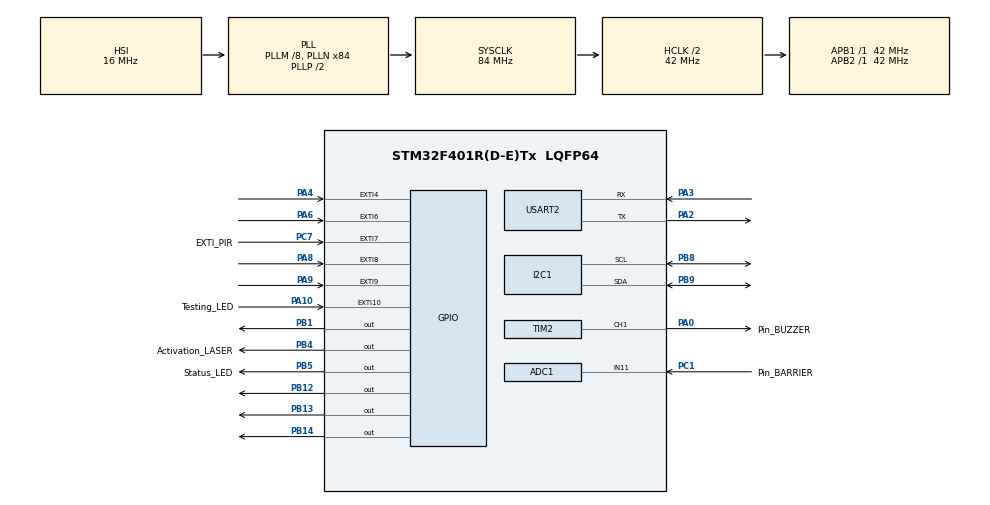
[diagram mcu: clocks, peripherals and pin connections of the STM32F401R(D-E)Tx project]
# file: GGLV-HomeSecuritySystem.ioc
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ADC1.Channel-0\#ChannelRegularConversion=ADC_CHANNEL_11
ADC1.NbrOfConversionFlag=1
ADC1.Rank-0\#ChannelRegularConversion=1
ADC1.SamplingTime-0\#ChannelRegularConversion=ADC_SAMPLETIME_3CYCLES
ADC1.master=1
Dma.I2C1_RX.0.Direction=DMA_PERIPH_TO_MEMORY
Dma.I2C1_RX.0.FIFOMode=DMA_FIFOMODE_DISABLE
Dma.I2C1_RX.0.Instance=DMA1_Stream0
Dma.I2C1_RX.0.MemDataAlignment=DMA_MDATAALIGN_BYTE
Dma.I2C1_RX.0.MemInc=DMA_MINC_ENABLE
Dma.I2C1_RX.0.Mode=DMA_NORMAL
Dma.I2C1_RX.0.PeriphDataAlignment=DMA_PDATAALIGN_BYTE
Dma.I2C1_RX.0.PeriphInc=DMA_PINC_DISABLE
Dma.I2C1_RX.0.Priority=DMA_PRIORITY_LOW
Dma.I2C1_TX.1.Direction=DMA_MEMORY_TO_PERIPH
Dma.I2C1_TX.1.FIFOMode=DMA_FIFOMODE_DISABLE
Dma.I2C1_TX.1.Instance=DMA1_Stream6
Dma.I2C1_TX.1.MemDataAlignment=DMA_MDATAALIGN_BYTE
Dma.I2C1_TX.1.MemInc=DMA_MINC_ENABLE
Dma.I2C1_TX.1.Mode=DMA_NORMAL
Dma.I2C1_TX.1.PeriphDataAlignment=DMA_PDATAALIGN_BYTE
Dma.I2C1_TX.1.PeriphInc=DMA_PINC_DISABLE
Dma.I2C1_TX.1.Priority=DMA_PRIORITY_LOW
Dma.Request0=I2C1_RX
Dma.Request1=I2C1_TX
Dma.Request2=USART2_RX
Dma.USART2_RX.2.Direction=DMA_PERIPH_TO_MEMORY
Dma.USART2_RX.2.FIFOMode=DMA_FIFOMODE_DISABLE
Dma.USART2_RX.2.Instance=DMA1_Stream5
Dma.USART2_RX.2.MemDataAlignment=DMA_MDATAALIGN_BYTE
Dma.USART2_RX.2.MemInc=DMA_MINC_ENABLE
Dma.USART2_RX.2.Mode=DMA_NORMAL
Dma.USART2_RX.2.PeriphDataAlignment=DMA_PDATAALIGN_BYTE
Dma.USART2_RX.2.PeriphInc=DMA_PINC_DISABLE
Dma.USART2_RX.2.Priority=DMA_PRIORITY_LOW
Mcu.Family=STM32F4
Mcu.Name=STM32F401R(D-E)Tx
Mcu.Package=LQFP64
NVIC.ADC_IRQn=true\:0\:0\:false\:false\:true\:true\:true
NVIC.DMA1_Stream0_IRQn=true\:0\:0\:false\:false\:true\:false\:true
NVIC.DMA1_Stream5_IRQn=true\:0\:0\:false\:false\:true\:false\:true
NVIC.DMA1_Stream6_IRQn=true\:0\:0\:false\:false\:true\:false\:true
NVIC.EXTI15_10_IRQn=true\:0\:0\:false\:false\:true\:true\:true
NVIC.EXTI4_IRQn=true\:0\:0\:false\:false\:true\:true\:true
NVIC.EXTI9_5_IRQn=true\:0\:0\:false\:false\:true\:true\:true
NVIC.I2C1_ER_IRQn=true\:0\:0\:false\:false\:true\:true\:true
NVIC.I2C1_EV_IRQn=true\:0\:0\:false\:false\:true\:true\:true
NVIC.PriorityGroup=NVIC_PRIORITYGROUP_4
NVIC.TIM1_TRG_COM_TIM11_IRQn=true\:0\:0\:false\:false\:true\:true\:true
NVIC.TIM1_UP_TIM10_IRQn=true\:0\:0\:false\:false\:true\:true\:true
NVIC.TIM2_IRQn=true\:0\:0\:false\:false\:true\:true\:true
NVIC.TIM3_IRQn=true\:0\:0\:false\:false\:true\:true\:true
NVIC.USART2_IRQn=true\:0\:0\:false\:false\:true\:true\:true
PA0-WKUP.GPIO_Label=Pin_BUZZER
PA0-WKUP.Signal=S_TIM2_CH1_ETR
PA10.GPIO_Label=Testing_LED
PA10.Signal=GPXTI10
PA2.Mode=Asynchronous
PA2.Signal=USART2_TX
PA3.Mode=Asynchronous
PA3.Signal=USART2_RX
PA4.Signal=GPXTI4
PA6.Signal=GPXTI6
PA8.Signal=GPXTI8
PA9.Signal=GPXTI9
PB1.Signal=GPIO_Output
PB12.Signal=GPIO_Output
PB13.Signal=GPIO_Output
PB14.Signal=GPIO_Output
PB4.GPIO_Label=Activation_LASER
PB4.Signal=GPIO_Output
PB5.GPIO_Label=Status_LED
PB5.Signal=GPIO_Output
PB8.Mode=I2C
PB8.Signal=I2C1_SCL
PB9.Mode=I2C
PB9.Signal=I2C1_SDA
PC1.GPIO_Label=Pin_BARRIER
PC1.Signal=ADCx_IN11
PC7.GPIO_Label=EXTI_PIR
PC7.Signal=GPXTI7
ProjectManager.HeapSize=0x200
ProjectManager.StackSize=0x400
ProjectManager.TargetToolchain=STM32CubeIDE
RCC.48MHZClocksFreq_Value=42000000
RCC.AHBCLKDivider=RCC_SYSCLK_DIV2
RCC.AHBFreq_Value=42000000
RCC.APB1Freq_Value=42000000
RCC.APB1TimFreq_Value=42000000
RCC.APB2Freq_Value=42000000
RCC.APB2TimFreq_Value=42000000
RCC.CortexFreq_Value=42000000
RCC.HCLKFreq_Value=42000000
RCC.HSE_VALUE=25000000
RCC.HSI_VALUE=16000000
RCC.LSE_VALUE=32768
RCC.PLLM=8
RCC.PLLN=84
RCC.SYSCLKFreq_VALUE=84000000
RCC.SYSCLKSource=RCC_SYSCLKSOURCE_PLLCLK
RCC.VCOOutputFreq_Value=168000000
SH.ADCx_IN11.0=ADC1_IN11,IN11
SH.S_TIM2_CH1_ETR.0=TIM2_CH1,PWM Generation1 CH1
TIM2.Channel-PWM\ Generation1\ CH1=TIM_CHANNEL_1
USART2.VirtualMode=VM_ASYNC
VP_TIM10_VS_ClockSourceINT.Mode=Enable_Timer
VP_TIM11_VS_ClockSourceINT.Mode=Enable_Timer
VP_TIM2_VS_ClockSourceINT.Mode=Internal
VP_TIM3_VS_ClockSourceINT.Mode=Internal
board=custom

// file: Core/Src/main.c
/* USER CODE BEGIN Header */
/**
  ******************************************************************************
  * @file           : main.c
  * @brief          : Main program body
  ******************************************************************************
  * @attention
  *
  * <h2><center>&copy; Copyright (c) 2020 STMicroelectronics.
  * All rights reserved.</center></h2>
  *
  * This software component is licensed by ST under BSD 3-Clause license,
  * the "License"; You may not use this file except in compliance with the
  * License. You may obtain a copy of the License at:
  *                        opensource.org/licenses/BSD-3-Clause
  *
  ******************************************************************************
  */
/* USER CODE END Header */

#include "main.h"
#include "adc.h"
#include "dma.h"
#include "i2c.h"
#include "tim.h"
#include "usart.h"
#include "gpio.h"
#include <stdlib.h>

void SystemClock_Config(void);

/* USER CODE BEGIN 0 */
extern _sensor_HandleTypeDef area;
extern _sensor_HandleTypeDef barrier;
extern _buzzer_HandleTypeDef buzzer;
extern _configuration conf;

/* USER CODE END 0 */

int main(void)
{

  /* MCU Configuration--------------------------------------------------------*/

  /* Reset of all peripherals, Initializes the Flash interface and the Systick. */
  HAL_Init();

  /* Configure the system clock */
  SystemClock_Config();

  /* Initialize all configured peripherals */

  MX_GPIO_Init();
  MX_DMA_Init();
  MX_ADC1_Init();
  MX_I2C1_Init();
  MX_TIM2_Init();
  MX_TIM3_Init();
  MX_TIM10_Init();
  MX_TIM11_Init();
  MX_USART2_UART_Init();

  /* USER CODE BEGIN 2 */

  /* INITIALIZATION OF ALL SYSTEM COMPONENT */
  AREA_Init();
  BARRIER_Init();
  BUZZER_Init();
  EEPROM_Init();
  KEYPDAD_Init();
  RTC_Init();

  reset_memory_config();

  init_protocol();

  HAL_GPIO_WritePin(Status_LED_GPIO_Port, Status_LED_Pin, GPIO_PIN_SET);

  /* USER CODE END 2 */

  /* Infinite loop */
   while (1)
  {
	  KEYPAD_Update();
  }
}

void SystemClock_Config(void)
{
  RCC_OscInitTypeDef RCC_OscInitStruct = {0};
  RCC_ClkInitTypeDef RCC_ClkInitStruct = {0};

  /** Configure the main internal regulator output voltage
  */
  __HAL_RCC_PWR_CLK_ENABLE();
  __HAL_PWR_VOLTAGESCALING_CONFIG(PWR_REGULATOR_VOLTAGE_SCALE2);
  /** Initializes the CPU, AHB and APB busses clocks
  */
  RCC_OscInitStruct.OscillatorType = RCC_OSCILLATORTYPE_HSI;
  RCC_OscInitStruct.HSIState = RCC_HSI_ON;
  RCC_OscInitStruct.HSICalibrationValue = RCC_HSICALIBRATION_DEFAULT;
  RCC_OscInitStruct.PLL.PLLState = RCC_PLL_ON;
  RCC_OscInitStruct.PLL.PLLSource = RCC_PLLSOURCE_HSI;
  RCC_OscInitStruct.PLL.PLLM = 8;
  RCC_OscInitStruct.PLL.PLLN = 84;
  RCC_OscInitStruct.PLL.PLLP = RCC_PLLP_DIV2;
  RCC_OscInitStruct.PLL.PLLQ = 4;
  if (HAL_RCC_OscConfig(&RCC_OscInitStruct) != HAL_OK)
  {
    Error_Handler();
  }
  /** Initializes the CPU, AHB and APB busses clocks
  */
  RCC_ClkInitStruct.ClockType = RCC_CLOCKTYPE_HCLK|RCC_CLOCKTYPE_SYSCLK
                              |RCC_CLOCKTYPE_PCLK1|RCC_CLOCKTYPE_PCLK2;
  RCC_ClkInitStruct.SYSCLKSource = RCC_SYSCLKSOURCE_PLLCLK;
  RCC_ClkInitStruct.AHBCLKDivider = RCC_SYSCLK_DIV2;
  RCC_ClkInitStruct.APB1CLKDivider = RCC_HCLK_DIV1;
  RCC_ClkInitStruct.APB2CLKDivider = RCC_HCLK_DIV1;

  if (HAL_RCC_ClockConfig(&RCC_ClkInitStruct, FLASH_LATENCY_1) != HAL_OK)
  {
    Error_Handler();
  }
}

void Error_Handler(void)
{
}

/************************ (C) COPYRIGHT STMicroelectronics *****END OF FILE****/
